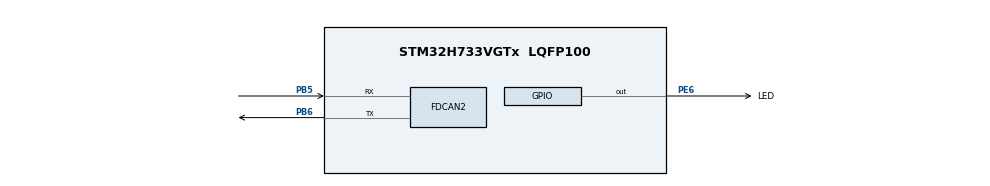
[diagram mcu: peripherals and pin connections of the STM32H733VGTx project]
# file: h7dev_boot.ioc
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CORTEX_M7.CPU_DCache=Disabled
CORTEX_M7.CPU_ICache=Disabled
FDCAN2.AutoRetransmission=ENABLE
FDCAN2.CalculateBaudRateNominal=500000
FDCAN2.CalculateTimeBitNominal=2000
FDCAN2.CalculateTimeQuantumNominal=125.0
FDCAN2.NominalPrescaler=6
FDCAN2.NominalSyncJumpWidth=4
FDCAN2.NominalTimeSeg1=13
FDCAN2.RxFifo0ElmtsNbr=1
FDCAN2.StdFiltersNbr=1
FDCAN2.TxFifoQueueElmtsNbr=1
Mcu.Family=STM32H7
Mcu.Name=STM32H733VGTx
Mcu.Package=LQFP100
NVIC.FDCAN2_IT0_IRQn=true\:5\:0\:true\:false\:true\:true\:true\:true
NVIC.FDCAN2_IT1_IRQn=true\:5\:0\:true\:false\:true\:true\:true\:true
NVIC.PriorityGroup=NVIC_PRIORITYGROUP_4
NVIC.TIM6_DAC_IRQn=true\:15\:0\:false\:false\:true\:false\:true\:true
NVIC.TimeBase=TIM6_DAC_IRQn
NVIC.TimeBaseIP=TIM6
PB5.Mode=FDCAN_Activate
PB5.Signal=FDCAN2_RX
PB6.Mode=FDCAN_Activate
PB6.Signal=FDCAN2_TX
PE6.GPIO_Label=LED
PE6.Signal=GPIO_Output
PH0-OSC_IN.Mode=HSE-External-Oscillator
PH0-OSC_IN.Signal=RCC_OSC_IN
PH1-OSC_OUT.Mode=HSE-External-Oscillator
PH1-OSC_OUT.Signal=RCC_OSC_OUT
ProjectManager.HeapSize=0x00
ProjectManager.StackSize=0x400
ProjectManager.TargetToolchain=STM32CubeIDE
RCC.ADCFreq_Value=16125000
RCC.APB1Freq_Value=24000000
RCC.APB2Freq_Value=24000000
RCC.APB3Freq_Value=24000000
RCC.APB4Freq_Value=24000000
RCC.CortexFreq_Value=96000000
RCC.D1CPRE=RCC_SYSCLK_DIV2
RCC.D1PPRE=RCC_APB3_DIV2
RCC.D2PPRE1=RCC_APB1_DIV2
RCC.D2PPRE2=RCC_APB2_DIV2
RCC.D3PPRE=RCC_APB4_DIV2
RCC.DIVM1=1
RCC.DIVN1=24
RCC.DIVP1=1
RCC.DIVQ1=4
RCC.HCLKFreq_Value=48000000
RCC.HPRE=RCC_HCLK_DIV2
RCC.HSE_VALUE=8000000
RCC.PLL2FRACN=0
RCC.PLL3FRACN=0
RCC.PLLFRACN=0
RCC.PLLSourceVirtual=RCC_PLLSOURCE_HSE
RCC.SYSCLKFreq_VALUE=192000000
RCC.SYSCLKSource=RCC_SYSCLKSOURCE_PLLCLK
RCC.USBFreq_Value=48000000
VP_SYS_VS_tim6.Mode=TIM6
board=custom

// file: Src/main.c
/* USER CODE BEGIN Header */
/**
 ******************************************************************************
 * @file           : main.c
 * @brief          : Main program body
 ******************************************************************************
 * @attention
 *
 * Copyright (c) 2023 STMicroelectronics.
 * All rights reserved.
 *
 * This software is licensed under terms that can be found in the LICENSE file
 * in the root directory of this software component.
 * If no LICENSE file comes with this software, it is provided AS-IS.
 *
 ******************************************************************************
 */
/* USER CODE END Header */
#include "main.h"

/* USER CODE BEGIN Includes */
#include "bootloader.h"
#include "hw_fdcan.h"
#include "io_canQueue.h"
#include "hw_error.h"
/* USER CODE END Includes */

FDCAN_HandleTypeDef hfdcan2;

void        SystemClock_Config(void);
static void MX_GPIO_Init(void);
static void MX_FDCAN2_Init(void);

int main(void)
{

    /* MCU Configuration--------------------------------------------------------*/

    /* Reset of all peripherals, Initializes the Flash interface and the Systick. */
    HAL_Init();

    /* Configure the system clock */
    SystemClock_Config();

    /* Initialize all configured peripherals */
    MX_GPIO_Init();
    MX_FDCAN2_Init();
    /* USER CODE BEGIN 2 */
    bootloader_init();
    /* USER CODE END 2 */

    /* Infinite loop */
    while (1)
    {

    }
}

void SystemClock_Config(void)
{
    RCC_OscInitTypeDef RCC_OscInitStruct = { 0 };
    RCC_ClkInitTypeDef RCC_ClkInitStruct = { 0 };

    /** Supply configuration update enable
     */
    HAL_PWREx_ConfigSupply(PWR_LDO_SUPPLY);

    /** Configure the main internal regulator output voltage
     */
    __HAL_PWR_VOLTAGESCALING_CONFIG(PWR_REGULATOR_VOLTAGE_SCALE3);

    while (!__HAL_PWR_GET_FLAG(PWR_FLAG_VOSRDY))
    {
    }

    /** Initializes the RCC Oscillators according to the specified parameters
     * in the RCC_OscInitTypeDef structure.
     */
    RCC_OscInitStruct.OscillatorType = RCC_OSCILLATORTYPE_HSE;
    RCC_OscInitStruct.HSEState       = RCC_HSE_ON;
    RCC_OscInitStruct.PLL.PLLState   = RCC_PLL_ON;
    RCC_OscInitStruct.PLL.PLLSource  = RCC_PLLSOURCE_HSE;
    RCC_OscInitStruct.PLL.PLLM       = 1;
    RCC_OscInitStruct.PLL.PLLN       = 24;
    RCC_OscInitStruct.PLL.PLLP       = 1;
    RCC_OscInitStruct.PLL.PLLQ       = 4;
    RCC_OscInitStruct.PLL.PLLR       = 2;
    RCC_OscInitStruct.PLL.PLLRGE     = RCC_PLL1VCIRANGE_3;
    RCC_OscInitStruct.PLL.PLLVCOSEL  = RCC_PLL1VCOWIDE;
    RCC_OscInitStruct.PLL.PLLFRACN   = 0;
    if (HAL_RCC_OscConfig(&RCC_OscInitStruct) != HAL_OK)
    {
        Error_Handler();
    }

    /** Initializes the CPU, AHB and APB buses clocks
     */
    RCC_ClkInitStruct.ClockType = RCC_CLOCKTYPE_HCLK | RCC_CLOCKTYPE_SYSCLK | RCC_CLOCKTYPE_PCLK1 |
                                  RCC_CLOCKTYPE_PCLK2 | RCC_CLOCKTYPE_D3PCLK1 | RCC_CLOCKTYPE_D1PCLK1;
    RCC_ClkInitStruct.SYSCLKSource   = RCC_SYSCLKSOURCE_PLLCLK;
    RCC_ClkInitStruct.SYSCLKDivider  = RCC_SYSCLK_DIV2;
    RCC_ClkInitStruct.AHBCLKDivider  = RCC_HCLK_DIV2;
    RCC_ClkInitStruct.APB3CLKDivider = RCC_APB3_DIV2;
    RCC_ClkInitStruct.APB1CLKDivider = RCC_APB1_DIV2;
    RCC_ClkInitStruct.APB2CLKDivider = RCC_APB2_DIV2;
    RCC_ClkInitStruct.APB4CLKDivider = RCC_APB4_DIV2;

    if (HAL_RCC_ClockConfig(&RCC_ClkInitStruct, FLASH_LATENCY_1) != HAL_OK)
    {
        Error_Handler();
    }
}

static void MX_FDCAN2_Init(void)
{

    hfdcan2.Instance                  = FDCAN2;
    hfdcan2.Init.FrameFormat          = FDCAN_FRAME_CLASSIC;
    hfdcan2.Init.Mode                 = FDCAN_MODE_NORMAL;
    hfdcan2.Init.AutoRetransmission   = ENABLE;
    hfdcan2.Init.TransmitPause        = DISABLE;
    hfdcan2.Init.ProtocolException    = DISABLE;
    hfdcan2.Init.NominalPrescaler     = 6;
    hfdcan2.Init.NominalSyncJumpWidth = 4;
    hfdcan2.Init.NominalTimeSeg1      = 13;
    hfdcan2.Init.NominalTimeSeg2      = 2;
    hfdcan2.Init.DataPrescaler        = 1;
    hfdcan2.Init.DataSyncJumpWidth    = 1;
    hfdcan2.Init.DataTimeSeg1         = 1;
    hfdcan2.Init.DataTimeSeg2         = 1;
    hfdcan2.Init.MessageRAMOffset     = 0;
    hfdcan2.Init.StdFiltersNbr        = 1;
    hfdcan2.Init.ExtFiltersNbr        = 0;
    hfdcan2.Init.RxFifo0ElmtsNbr      = 1;
    hfdcan2.Init.RxFifo0ElmtSize      = FDCAN_DATA_BYTES_8;
    hfdcan2.Init.RxFifo1ElmtsNbr      = 0;
    hfdcan2.Init.RxFifo1ElmtSize      = FDCAN_DATA_BYTES_8;
    hfdcan2.Init.RxBuffersNbr         = 0;
    hfdcan2.Init.RxBufferSize         = FDCAN_DATA_BYTES_8;
    hfdcan2.Init.TxEventsNbr          = 0;
    hfdcan2.Init.TxBuffersNbr         = 0;
    hfdcan2.Init.TxFifoQueueElmtsNbr  = 1;
    hfdcan2.Init.TxFifoQueueMode      = FDCAN_TX_FIFO_OPERATION;
    hfdcan2.Init.TxElmtSize           = FDCAN_DATA_BYTES_8;
    if (HAL_FDCAN_Init(&hfdcan2) != HAL_OK)
    {
        Error_Handler();
    }
}

static void MX_GPIO_Init(void)
{
    GPIO_InitTypeDef GPIO_InitStruct = { 0 };

    /* GPIO Ports Clock Enable */
    __HAL_RCC_GPIOE_CLK_ENABLE();
    __HAL_RCC_GPIOH_CLK_ENABLE();
    __HAL_RCC_GPIOB_CLK_ENABLE();

    /*Configure GPIO pin Output Level */
    HAL_GPIO_WritePin(LED_GPIO_Port, LED_Pin, GPIO_PIN_RESET);

    /*Configure GPIO pin : LED_Pin */
    GPIO_InitStruct.Pin   = LED_Pin;
    GPIO_InitStruct.Mode  = GPIO_MODE_OUTPUT_PP;
    GPIO_InitStruct.Pull  = GPIO_NOPULL;
    GPIO_InitStruct.Speed = GPIO_SPEED_FREQ_LOW;
    HAL_GPIO_Init(LED_GPIO_Port, &GPIO_InitStruct);

}

void HAL_TIM_PeriodElapsedCallback(TIM_HandleTypeDef *htim)
{
    if (htim->Instance == TIM6)
    {
        HAL_IncTick();
    }
}

void Error_Handler(void)
{
    __disable_irq();
    while (1)
    {
    }
}
